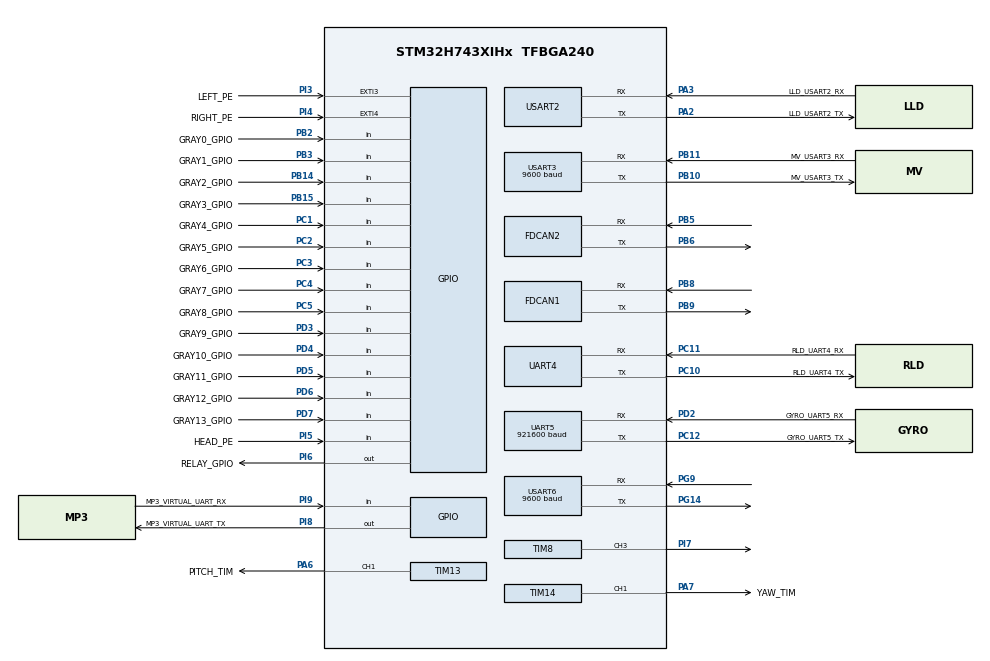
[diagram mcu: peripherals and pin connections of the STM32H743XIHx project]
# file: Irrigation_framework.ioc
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CORTEX_M7.AccessPermission_Spec=MPU_REGION_FULL_ACCESS
CORTEX_M7.BaseAddress_Spec=0x24000000
CORTEX_M7.CPU_DCache=Enabled
CORTEX_M7.CPU_ICache=Enabled
CORTEX_M7.DisableExec_Spec=MPU_INSTRUCTION_ACCESS_ENABLE
CORTEX_M7.Enable_Spec=MPU_REGION_ENABLE
CORTEX_M7.IsBufferable_Spec=MPU_ACCESS_NOT_BUFFERABLE
CORTEX_M7.IsCacheable_Spec=MPU_ACCESS_NOT_CACHEABLE
CORTEX_M7.IsShareable_Spec=MPU_ACCESS_NOT_SHAREABLE
CORTEX_M7.MPU_Control=MPU_PRIVILEGED_DEFAULT
CORTEX_M7.Size_Spec=MPU_REGION_SIZE_2KB
CORTEX_M7.SubRegionDisable_Spec=0x0
CORTEX_M7.TypeExtField_Spec=MPU_TEX_LEVEL1
CORTEX_M7.default_mode_Activation=1
Dma.Request0=USART2_RX
Dma.Request1=USART3_RX
Dma.Request2=UART4_RX
Dma.Request3=UART5_RX
Dma.UART4_RX.2.Direction=DMA_PERIPH_TO_MEMORY
Dma.UART4_RX.2.EventEnable=DISABLE
Dma.UART4_RX.2.FIFOMode=DMA_FIFOMODE_DISABLE
Dma.UART4_RX.2.Instance=DMA1_Stream3
Dma.UART4_RX.2.MemDataAlignment=DMA_MDATAALIGN_BYTE
Dma.UART4_RX.2.MemInc=DMA_MINC_ENABLE
Dma.UART4_RX.2.Mode=DMA_NORMAL
Dma.UART4_RX.2.PeriphDataAlignment=DMA_PDATAALIGN_BYTE
Dma.UART4_RX.2.PeriphInc=DMA_PINC_DISABLE
Dma.UART4_RX.2.Polarity=HAL_DMAMUX_REQ_GEN_RISING
Dma.UART4_RX.2.Priority=DMA_PRIORITY_MEDIUM
Dma.UART4_RX.2.RequestNumber=1
Dma.UART4_RX.2.SignalID=NONE
Dma.UART4_RX.2.SyncEnable=DISABLE
Dma.UART4_RX.2.SyncPolarity=HAL_DMAMUX_SYNC_NO_EVENT
Dma.UART4_RX.2.SyncRequestNumber=1
Dma.UART4_RX.2.SyncSignalID=NONE
Dma.UART5_RX.3.Direction=DMA_PERIPH_TO_MEMORY
Dma.UART5_RX.3.EventEnable=DISABLE
Dma.UART5_RX.3.FIFOMode=DMA_FIFOMODE_DISABLE
Dma.UART5_RX.3.Instance=DMA1_Stream4
Dma.UART5_RX.3.MemDataAlignment=DMA_MDATAALIGN_BYTE
Dma.UART5_RX.3.MemInc=DMA_MINC_ENABLE
Dma.UART5_RX.3.Mode=DMA_NORMAL
Dma.UART5_RX.3.PeriphDataAlignment=DMA_PDATAALIGN_BYTE
Dma.UART5_RX.3.PeriphInc=DMA_PINC_DISABLE
Dma.UART5_RX.3.Polarity=HAL_DMAMUX_REQ_GEN_RISING
Dma.UART5_RX.3.Priority=DMA_PRIORITY_HIGH
Dma.UART5_RX.3.RequestNumber=1
Dma.UART5_RX.3.SignalID=NONE
Dma.UART5_RX.3.SyncEnable=DISABLE
Dma.UART5_RX.3.SyncPolarity=HAL_DMAMUX_SYNC_NO_EVENT
Dma.UART5_RX.3.SyncRequestNumber=1
Dma.UART5_RX.3.SyncSignalID=NONE
Dma.USART2_RX.0.Direction=DMA_PERIPH_TO_MEMORY
Dma.USART2_RX.0.EventEnable=DISABLE
Dma.USART2_RX.0.FIFOMode=DMA_FIFOMODE_DISABLE
Dma.USART2_RX.0.Instance=DMA1_Stream1
Dma.USART2_RX.0.MemDataAlignment=DMA_MDATAALIGN_BYTE
Dma.USART2_RX.0.MemInc=DMA_MINC_ENABLE
Dma.USART2_RX.0.Mode=DMA_NORMAL
Dma.USART2_RX.0.PeriphDataAlignment=DMA_PDATAALIGN_BYTE
Dma.USART2_RX.0.PeriphInc=DMA_PINC_DISABLE
Dma.USART2_RX.0.Polarity=HAL_DMAMUX_REQ_GEN_RISING
Dma.USART2_RX.0.Priority=DMA_PRIORITY_MEDIUM
Dma.USART2_RX.0.RequestNumber=1
Dma.USART2_RX.0.SignalID=NONE
Dma.USART2_RX.0.SyncEnable=DISABLE
Dma.USART2_RX.0.SyncPolarity=HAL_DMAMUX_SYNC_NO_EVENT
Dma.USART2_RX.0.SyncRequestNumber=1
Dma.USART2_RX.0.SyncSignalID=NONE
Dma.USART3_RX.1.Direction=DMA_PERIPH_TO_MEMORY
Dma.USART3_RX.1.EventEnable=DISABLE
Dma.USART3_RX.1.FIFOMode=DMA_FIFOMODE_DISABLE
Dma.USART3_RX.1.Instance=DMA1_Stream2
Dma.USART3_RX.1.MemDataAlignment=DMA_MDATAALIGN_BYTE
Dma.USART3_RX.1.MemInc=DMA_MINC_ENABLE
Dma.USART3_RX.1.Mode=DMA_NORMAL
Dma.USART3_RX.1.PeriphDataAlignment=DMA_PDATAALIGN_BYTE
Dma.USART3_RX.1.PeriphInc=DMA_PINC_DISABLE
Dma.USART3_RX.1.Polarity=HAL_DMAMUX_REQ_GEN_RISING
Dma.USART3_RX.1.Priority=DMA_PRIORITY_HIGH
Dma.USART3_RX.1.RequestNumber=1
Dma.USART3_RX.1.SignalID=NONE
Dma.USART3_RX.1.SyncEnable=DISABLE
Dma.USART3_RX.1.SyncPolarity=HAL_DMAMUX_SYNC_NO_EVENT
Dma.USART3_RX.1.SyncRequestNumber=1
Dma.USART3_RX.1.SyncSignalID=NONE
FDCAN1.AutoRetransmission=ENABLE
FDCAN1.CalculateBaudRateNominal=1000000
FDCAN1.CalculateTimeBitNominal=1000
FDCAN1.CalculateTimeQuantumNominal=100.0
FDCAN1.DataPrescaler=12
FDCAN1.DataSyncJumpWidth=2
FDCAN1.DataTimeSeg1=7
FDCAN1.DataTimeSeg2=2
FDCAN1.NominalPrescaler=12
FDCAN1.NominalSyncJumpWidth=2
FDCAN1.NominalTimeSeg1=7
FDCAN1.ProtocolException=ENABLE
FDCAN1.RxFifo0ElmtsNbr=32
FDCAN1.StdFiltersNbr=1
FDCAN1.TxFifoQueueElmtsNbr=16
FDCAN2.AutoRetransmission=ENABLE
FDCAN2.CalculateBaudRateNominal=500000
FDCAN2.CalculateTimeBitNominal=2000
FDCAN2.CalculateTimeQuantumNominal=200.0
FDCAN2.DataPrescaler=12
FDCAN2.DataSyncJumpWidth=2
FDCAN2.DataTimeSeg1=7
FDCAN2.DataTimeSeg2=2
FDCAN2.NominalPrescaler=24
FDCAN2.NominalSyncJumpWidth=2
FDCAN2.NominalTimeSeg1=7
FDCAN2.ProtocolException=ENABLE
FDCAN2.RxFifo0ElmtsNbr=32
FDCAN2.StdFiltersNbr=1
FDCAN2.TxFifoQueueElmtsNbr=16
FREERTOS.INCLUDE_uxTaskGetStackHighWaterMark=1
FREERTOS.Tasks01=defaultTask,0,128,StartDefaultTask,Default,NULL,Dynamic,NULL,NULL
FREERTOS.configCHECK_FOR_STACK_OVERFLOW=2
FREERTOS.configENABLE_FPU=1
FREERTOS.configTOTAL_HEAP_SIZE=40960
FREERTOS.configUSE_MALLOC_FAILED_HOOK=0
FREERTOS.configUSE_TIMERS=1
Mcu.Family=STM32H7
Mcu.Name=STM32H743XIHx
Mcu.Package=TFBGA240
NVIC.DMA1_Stream1_IRQn=true\:5\:0\:false\:false\:true\:true\:false\:true\:true
NVIC.DMA1_Stream2_IRQn=true\:5\:0\:false\:false\:true\:true\:false\:true\:true
NVIC.DMA1_Stream3_IRQn=true\:5\:0\:false\:false\:true\:true\:false\:true\:true
NVIC.DMA1_Stream4_IRQn=true\:5\:0\:false\:false\:true\:true\:false\:true\:true
NVIC.EXTI3_IRQn=true\:5\:0\:true\:false\:true\:true\:true\:true\:true
NVIC.EXTI4_IRQn=true\:5\:0\:true\:false\:true\:true\:true\:true\:true
NVIC.FDCAN1_IT0_IRQn=true\:6\:0\:true\:false\:true\:true\:true\:true\:true
NVIC.FDCAN1_IT1_IRQn=true\:6\:0\:true\:false\:true\:true\:true\:true\:true
NVIC.FDCAN2_IT0_IRQn=true\:5\:0\:false\:false\:true\:true\:true\:true\:true
NVIC.FDCAN2_IT1_IRQn=true\:5\:0\:false\:false\:true\:true\:true\:true\:true
NVIC.PriorityGroup=NVIC_PRIORITYGROUP_4
NVIC.TIM1_UP_IRQn=true\:15\:0\:true\:false\:true\:false\:false\:true\:true
NVIC.TimeBase=TIM1_UP_IRQn
NVIC.TimeBaseIP=TIM1
NVIC.UART4_IRQn=true\:6\:0\:true\:false\:true\:true\:true\:true\:true
NVIC.UART5_IRQn=true\:6\:0\:true\:false\:true\:true\:true\:true\:true
NVIC.USART2_IRQn=true\:6\:0\:true\:false\:true\:true\:true\:true\:true
NVIC.USART3_IRQn=true\:6\:0\:true\:false\:true\:true\:true\:true\:true
NVIC.USART6_IRQn=true\:5\:0\:false\:false\:true\:true\:true\:true\:true
PA13\ (JTMS/SWDIO).Mode=Serial_Wire
PA13\ (JTMS/SWDIO).Signal=DEBUG_JTMS-SWDIO
PA14\ (JTCK/SWCLK).Mode=Serial_Wire
PA14\ (JTCK/SWCLK).Signal=DEBUG_JTCK-SWCLK
PA2.GPIO_Label=LLD_USART2_TX
PA2.Mode=Asynchronous
PA2.Signal=USART2_TX
PA3.GPIO_Label=LLD_USART2_RX
PA3.Mode=Asynchronous
PA3.Signal=USART2_RX
PA6.GPIO_Label=PITCH_TIM
PA6.GPIO_PuPd=GPIO_PULLDOWN
PA6.GPIO_Speed=GPIO_SPEED_FREQ_HIGH
PA6.Signal=S_TIM13_CH1
PA7.GPIO_Label=YAW_TIM
PA7.GPIO_PuPd=GPIO_PULLUP
PA7.GPIO_Speed=GPIO_SPEED_FREQ_HIGH
PA7.Signal=S_TIM14_CH1
PB10.GPIO_Label=MV_USART3_TX
PB10.Mode=Asynchronous
PB10.Signal=USART3_TX
PB11.GPIO_Label=MV_USART3_RX
PB11.Mode=Asynchronous
PB11.Signal=USART3_RX
PB14.GPIO_Label=GRAY2_GPIO
PB14.GPIO_PuPd=GPIO_PULLUP
PB14.Signal=GPIO_Input
PB15.GPIO_Label=GRAY3_GPIO
PB15.GPIO_PuPd=GPIO_PULLUP
PB15.Signal=GPIO_Input
PB2.GPIO_Label=GRAY0_GPIO
PB2.GPIO_PuPd=GPIO_PULLUP
PB2.Signal=GPIO_Input
PB3\ (JTDO/TRACESWO).GPIO_Label=GRAY1_GPIO
PB3\ (JTDO/TRACESWO).GPIO_PuPd=GPIO_PULLUP
PB3\ (JTDO/TRACESWO).Signal=GPIO_Input
PB5.GPIO_Speed=GPIO_SPEED_FREQ_HIGH
PB5.Mode=FDCAN_Activate
PB5.Signal=FDCAN2_RX
PB6.GPIO_Speed=GPIO_SPEED_FREQ_HIGH
PB6.Mode=FDCAN_Activate
PB6.Signal=FDCAN2_TX
PB8.GPIO_Speed=GPIO_SPEED_FREQ_HIGH
PB8.Mode=FDCAN_Activate
PB8.Signal=FDCAN1_RX
PB9.GPIO_Speed=GPIO_SPEED_FREQ_HIGH
PB9.Mode=FDCAN_Activate
PB9.Signal=FDCAN1_TX
PC1.GPIO_Label=GRAY4_GPIO
PC1.GPIO_PuPd=GPIO_PULLUP
PC1.Signal=GPIO_Input
PC10.GPIO_Label=RLD_UART4_TX
PC10.Mode=Asynchronous
PC10.Signal=UART4_TX
PC11.GPIO_Label=RLD_UART4_RX
PC11.Mode=Asynchronous
PC11.Signal=UART4_RX
PC12.GPIO_Label=GYRO_UART5_TX
PC12.Mode=Asynchronous
PC12.Signal=UART5_TX
PC14-OSC32_IN\ (OSC32_IN).Mode=LSE-External-Oscillator
PC14-OSC32_IN\ (OSC32_IN).Signal=RCC_OSC32_IN
PC15-OSC32_OUT\ (OSC32_OUT).Mode=LSE-External-Oscillator
PC15-OSC32_OUT\ (OSC32_OUT).Signal=RCC_OSC32_OUT
PC2.GPIO_Label=GRAY5_GPIO
PC2.GPIO_PuPd=GPIO_PULLUP
PC2.Signal=GPIO_Input
PC3.GPIO_Label=GRAY6_GPIO
PC3.GPIO_PuPd=GPIO_PULLUP
PC3.Signal=GPIO_Input
PC4.GPIO_Label=GRAY7_GPIO
PC4.GPIO_PuPd=GPIO_PULLUP
PC4.Signal=GPIO_Input
PC5.GPIO_Label=GRAY8_GPIO
PC5.GPIO_PuPd=GPIO_PULLUP
PC5.Signal=GPIO_Input
PD2.GPIO_Label=GYRO_UART5_RX
PD2.Mode=Asynchronous
PD2.Signal=UART5_RX
PD3.GPIO_Label=GRAY9_GPIO
PD3.GPIO_PuPd=GPIO_PULLUP
PD3.Signal=GPIO_Input
PD4.GPIO_Label=GRAY10_GPIO
PD4.GPIO_PuPd=GPIO_PULLUP
PD4.Signal=GPIO_Input
PD5.GPIO_Label=GRAY11_GPIO
PD5.GPIO_PuPd=GPIO_PULLUP
PD5.Signal=GPIO_Input
PD6.GPIO_Label=GRAY12_GPIO
PD6.GPIO_PuPd=GPIO_PULLUP
PD6.Signal=GPIO_Input
PD7.GPIO_Label=GRAY13_GPIO
PD7.GPIO_PuPd=GPIO_PULLUP
PD7.Signal=GPIO_Input
PG14.Mode=Asynchronous
PG14.Signal=USART6_TX
PG9.Mode=Asynchronous
PG9.Signal=USART6_RX
PH0-OSC_IN\ (PH0).Mode=HSE-External-Oscillator
PH0-OSC_IN\ (PH0).Signal=RCC_OSC_IN
PH1-OSC_OUT\ (PH1).Mode=HSE-External-Oscillator
PH1-OSC_OUT\ (PH1).Signal=RCC_OSC_OUT
PI3.GPIO_Label=LEFT_PE
PI3.GPIO_ModeDefaultEXTI=GPIO_MODE_IT_FALLING
PI3.GPIO_PuPd=GPIO_PULLUP
PI3.Signal=GPXTI3
PI4.GPIO_Label=RIGHT_PE
PI4.GPIO_ModeDefaultEXTI=GPIO_MODE_IT_FALLING
PI4.GPIO_PuPd=GPIO_PULLUP
PI4.Signal=GPXTI4
PI5.GPIO_Label=HEAD_PE
PI5.GPIO_PuPd=GPIO_PULLUP
PI5.Signal=GPIO_Input
PI6.GPIO_Label=RELAY_GPIO
PI6.GPIO_PuPd=GPIO_PULLUP
PI6.GPIO_Speed=GPIO_SPEED_FREQ_VERY_HIGH
PI6.PinState=GPIO_PIN_RESET
PI6.Signal=GPIO_Output
PI7.Signal=S_TIM8_CH3
PI8.GPIO_Label=MP3_VIRTUAL_UART_TX
PI8.GPIO_PuPd=GPIO_PULLUP
PI8.PinState=GPIO_PIN_RESET
PI8.Signal=GPIO_Output
PI9.GPIO_Label=MP3_VIRTUAL_UART_RX
PI9.GPIO_PuPd=GPIO_PULLUP
PI9.Signal=GPIO_Input
ProjectManager.HeapSize=0x2000
ProjectManager.StackSize=0x4000
ProjectManager.TargetToolchain=Makefile
RCC.ADCFreq_Value=129000000
RCC.APB1Freq_Value=120000000
RCC.APB2Freq_Value=120000000
RCC.APB3Freq_Value=120000000
RCC.APB4Freq_Value=120000000
RCC.CortexFreq_Value=480000000
RCC.D1PPRE=RCC_APB3_DIV2
RCC.D2PPRE1=RCC_APB1_DIV2
RCC.D2PPRE2=RCC_APB2_DIV2
RCC.D3PPRE=RCC_APB4_DIV2
RCC.DIVM1=4
RCC.DIVN1=60
RCC.DIVQ1=8
RCC.HCLKFreq_Value=240000000
RCC.HPRE=RCC_HCLK_DIV2
RCC.PLL2FRACN=0
RCC.PLL3FRACN=0
RCC.PLLFRACN=0
RCC.SYSCLKFreq_VALUE=480000000
RCC.SYSCLKSource=RCC_SYSCLKSOURCE_PLLCLK
RCC.USBFreq_Value=120000000
SH.S_TIM13_CH1.0=TIM13_CH1,PWM Generation1 CH1
SH.S_TIM14_CH1.0=TIM14_CH1,PWM Generation1 CH1
SH.S_TIM8_CH3.0=TIM8_CH3,PWM Generation3 CH3
STMicroelectronics.X-CUBE-ALGOBUILD.1.4.0.LibraryCcDSPOoLibraryJjDSPOoLibrary=true
TIM13.AutoReloadPreload=TIM_AUTORELOAD_PRELOAD_ENABLE
TIM13.Channel=TIM_CHANNEL_1
TIM13.Period=19999
TIM13.Prescaler=239
TIM14.AutoReloadPreload=TIM_AUTORELOAD_PRELOAD_ENABLE
TIM14.Channel=TIM_CHANNEL_1
TIM14.Period=19999
TIM14.Prescaler=239
TIM8.Channel-PWM\ Generation3\ CH3=TIM_CHANNEL_3
TIM8.Prescaler=479
UART5.BaudRate=921600
USART2.VirtualMode-Asynchronous=VM_ASYNC
USART3.BaudRate=9600
USART3.VirtualMode-Asynchronous=VM_ASYNC
USART6.BaudRate=9600
USART6.Mode=MODE_TX
USART6.VirtualMode-Asynchronous=VM_ASYNC
VP_CRC_VS_CRC.Mode=CRC_Activate
VP_FREERTOS_VS_CMSIS_V1.Mode=CMSIS_V1
VP_MEMORYMAP_VS_MEMORYMAP.Mode=CurAppReg
VP_RNG_VS_RNG.Mode=RNG_Activate
VP_RTC_VS_RTC_Activate.Mode=RTC_Enabled
VP_STMicroelectronics.X-CUBE-ALGOBUILD_VS_DSPOoLibraryJjLibrary_1.4.0_1.4.0.Mode=DSPOoLibraryJjLibrary
VP_SYS_VS_tim1.Mode=TIM1
VP_TIM13_VS_ClockSourceINT.Mode=Enable_Timer
VP_TIM14_VS_ClockSourceINT.Mode=Enable_Timer
board=custom

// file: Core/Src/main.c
/* USER CODE BEGIN Header */
/**
 ******************************************************************************
 * @file           : main.c
 * @brief          : Main program body
 ******************************************************************************
 * @attention
 *
 * Copyright (c) 2024 STMicroelectronics.
 * All rights reserved.
 *
 * This software is licensed under terms that can be found in the LICENSE file
 * in the root directory of this software component.
 * If no LICENSE file comes with this software, it is provided AS-IS.
 *
 ******************************************************************************
 */
/* USER CODE END Header */
#include "main.h"
#include "cmsis_os.h"
#include "crc.h"
#include "dma.h"
#include "fdcan.h"
#include "memorymap.h"
#include "rng.h"
#include "rtc.h"
#include "tim.h"
#include "usart.h"
#include "gpio.h"

/* USER CODE BEGIN Includes */
#include "bsp_usart.h"
#include "robot.h"
// static BLUETOOTH_data_t *bluetooth_data;

/* USER CODE END Includes */

void SystemClock_Config(void);
static void MPU_Config(void);
void MX_FREERTOS_Init(void);

int main(void)
{

  /* MPU Configuration--------------------------------------------------------*/
  MPU_Config();

  /* Enable the CPU Cache */

  /* Enable I-Cache---------------------------------------------------------*/
  SCB_EnableICache();

  /* Enable D-Cache---------------------------------------------------------*/
  SCB_EnableDCache();

  /* MCU Configuration--------------------------------------------------------*/

  /* Reset of all peripherals, Initializes the Flash interface and the Systick. */
  HAL_Init();

  /* Configure the system clock */
  SystemClock_Config();

  /* Initialize all configured peripherals */
  MX_GPIO_Init();
  MX_DMA_Init();
  MX_USART2_UART_Init();
  MX_USART3_UART_Init();
  MX_UART4_Init();
  MX_UART5_Init();
  MX_TIM13_Init();
  MX_TIM14_Init();
  MX_CRC_Init();
  MX_FDCAN1_Init();
  MX_RNG_Init();
  MX_RTC_Init();
  MX_TIM8_Init();
  MX_FDCAN2_Init();
  MX_USART6_UART_Init();
  /* USER CODE BEGIN 2 */
  // bluetooth_data = Bluetooth_Init(&huart6);
  // while (1)
  //   ;
  // HAL_UART_Abort_IT(&huart6);
  RobotInit();
  init_my_section();
  /*       for testing       */

  /* USER CODE END 2 */

  /* Call init function for freertos objects (in cmsis_os2.c) */
  MX_FREERTOS_Init();

  /* Start scheduler */
  osKernelStart();

  /* We should never get here as control is now taken by the scheduler */

  /* Infinite loop */
  while (1)
  {

  }
}

void SystemClock_Config(void)
{
  RCC_OscInitTypeDef RCC_OscInitStruct = {0};
  RCC_ClkInitTypeDef RCC_ClkInitStruct = {0};

  /** Supply configuration update enable
  */
  HAL_PWREx_ConfigSupply(PWR_LDO_SUPPLY);

  /** Configure the main internal regulator output voltage
  */
  __HAL_PWR_VOLTAGESCALING_CONFIG(PWR_REGULATOR_VOLTAGE_SCALE1);

  while(!__HAL_PWR_GET_FLAG(PWR_FLAG_VOSRDY)) {}

  __HAL_RCC_SYSCFG_CLK_ENABLE();
  __HAL_PWR_VOLTAGESCALING_CONFIG(PWR_REGULATOR_VOLTAGE_SCALE0);

  while(!__HAL_PWR_GET_FLAG(PWR_FLAG_VOSRDY)) {}

  /** Initializes the RCC Oscillators according to the specified parameters
  * in the RCC_OscInitTypeDef structure.
  */
  RCC_OscInitStruct.OscillatorType = RCC_OSCILLATORTYPE_HSI48|RCC_OSCILLATORTYPE_HSI
                              |RCC_OSCILLATORTYPE_LSI;
  RCC_OscInitStruct.HSIState = RCC_HSI_DIV1;
  RCC_OscInitStruct.HSICalibrationValue = RCC_HSICALIBRATION_DEFAULT;
  RCC_OscInitStruct.LSIState = RCC_LSI_ON;
  RCC_OscInitStruct.HSI48State = RCC_HSI48_ON;
  RCC_OscInitStruct.PLL.PLLState = RCC_PLL_ON;
  RCC_OscInitStruct.PLL.PLLSource = RCC_PLLSOURCE_HSI;
  RCC_OscInitStruct.PLL.PLLM = 4;
  RCC_OscInitStruct.PLL.PLLN = 60;
  RCC_OscInitStruct.PLL.PLLP = 2;
  RCC_OscInitStruct.PLL.PLLQ = 8;
  RCC_OscInitStruct.PLL.PLLR = 2;
  RCC_OscInitStruct.PLL.PLLRGE = RCC_PLL1VCIRANGE_3;
  RCC_OscInitStruct.PLL.PLLVCOSEL = RCC_PLL1VCOWIDE;
  RCC_OscInitStruct.PLL.PLLFRACN = 0;
  if (HAL_RCC_OscConfig(&RCC_OscInitStruct) != HAL_OK)
  {
    Error_Handler();
  }

  /** Initializes the CPU, AHB and APB buses clocks
  */
  RCC_ClkInitStruct.ClockType = RCC_CLOCKTYPE_HCLK|RCC_CLOCKTYPE_SYSCLK
                              |RCC_CLOCKTYPE_PCLK1|RCC_CLOCKTYPE_PCLK2
                              |RCC_CLOCKTYPE_D3PCLK1|RCC_CLOCKTYPE_D1PCLK1;
  RCC_ClkInitStruct.SYSCLKSource = RCC_SYSCLKSOURCE_PLLCLK;
  RCC_ClkInitStruct.SYSCLKDivider = RCC_SYSCLK_DIV1;
  RCC_ClkInitStruct.AHBCLKDivider = RCC_HCLK_DIV2;
  RCC_ClkInitStruct.APB3CLKDivider = RCC_APB3_DIV2;
  RCC_ClkInitStruct.APB1CLKDivider = RCC_APB1_DIV2;
  RCC_ClkInitStruct.APB2CLKDivider = RCC_APB2_DIV2;
  RCC_ClkInitStruct.APB4CLKDivider = RCC_APB4_DIV2;

  if (HAL_RCC_ClockConfig(&RCC_ClkInitStruct, FLASH_LATENCY_4) != HAL_OK)
  {
    Error_Handler();
  }
}

 /* MPU Configuration */

void MPU_Config(void)
{
  MPU_Region_InitTypeDef MPU_InitStruct = {0};

  /* Disables the MPU */
  HAL_MPU_Disable();

  /** Initializes and configures the Region and the memory to be protected
  */
  MPU_InitStruct.Enable = MPU_REGION_ENABLE;
  MPU_InitStruct.Number = MPU_REGION_NUMBER0;
  MPU_InitStruct.BaseAddress = 0x24000000;
  MPU_InitStruct.Size = MPU_REGION_SIZE_2KB;
  MPU_InitStruct.SubRegionDisable = 0x0;
  MPU_InitStruct.TypeExtField = MPU_TEX_LEVEL1;
  MPU_InitStruct.AccessPermission = MPU_REGION_FULL_ACCESS;
  MPU_InitStruct.DisableExec = MPU_INSTRUCTION_ACCESS_ENABLE;
  MPU_InitStruct.IsShareable = MPU_ACCESS_NOT_SHAREABLE;
  MPU_InitStruct.IsCacheable = MPU_ACCESS_NOT_CACHEABLE;
  MPU_InitStruct.IsBufferable = MPU_ACCESS_NOT_BUFFERABLE;

  HAL_MPU_ConfigRegion(&MPU_InitStruct);
  /* Enables the MPU */
  HAL_MPU_Enable(MPU_PRIVILEGED_DEFAULT);

}

void HAL_TIM_PeriodElapsedCallback(TIM_HandleTypeDef *htim)
{
  if (htim->Instance == TIM1) {
    HAL_IncTick();
  }
}

void Error_Handler(void)
{
  __disable_irq();
  while (1)
  {
  }
}
